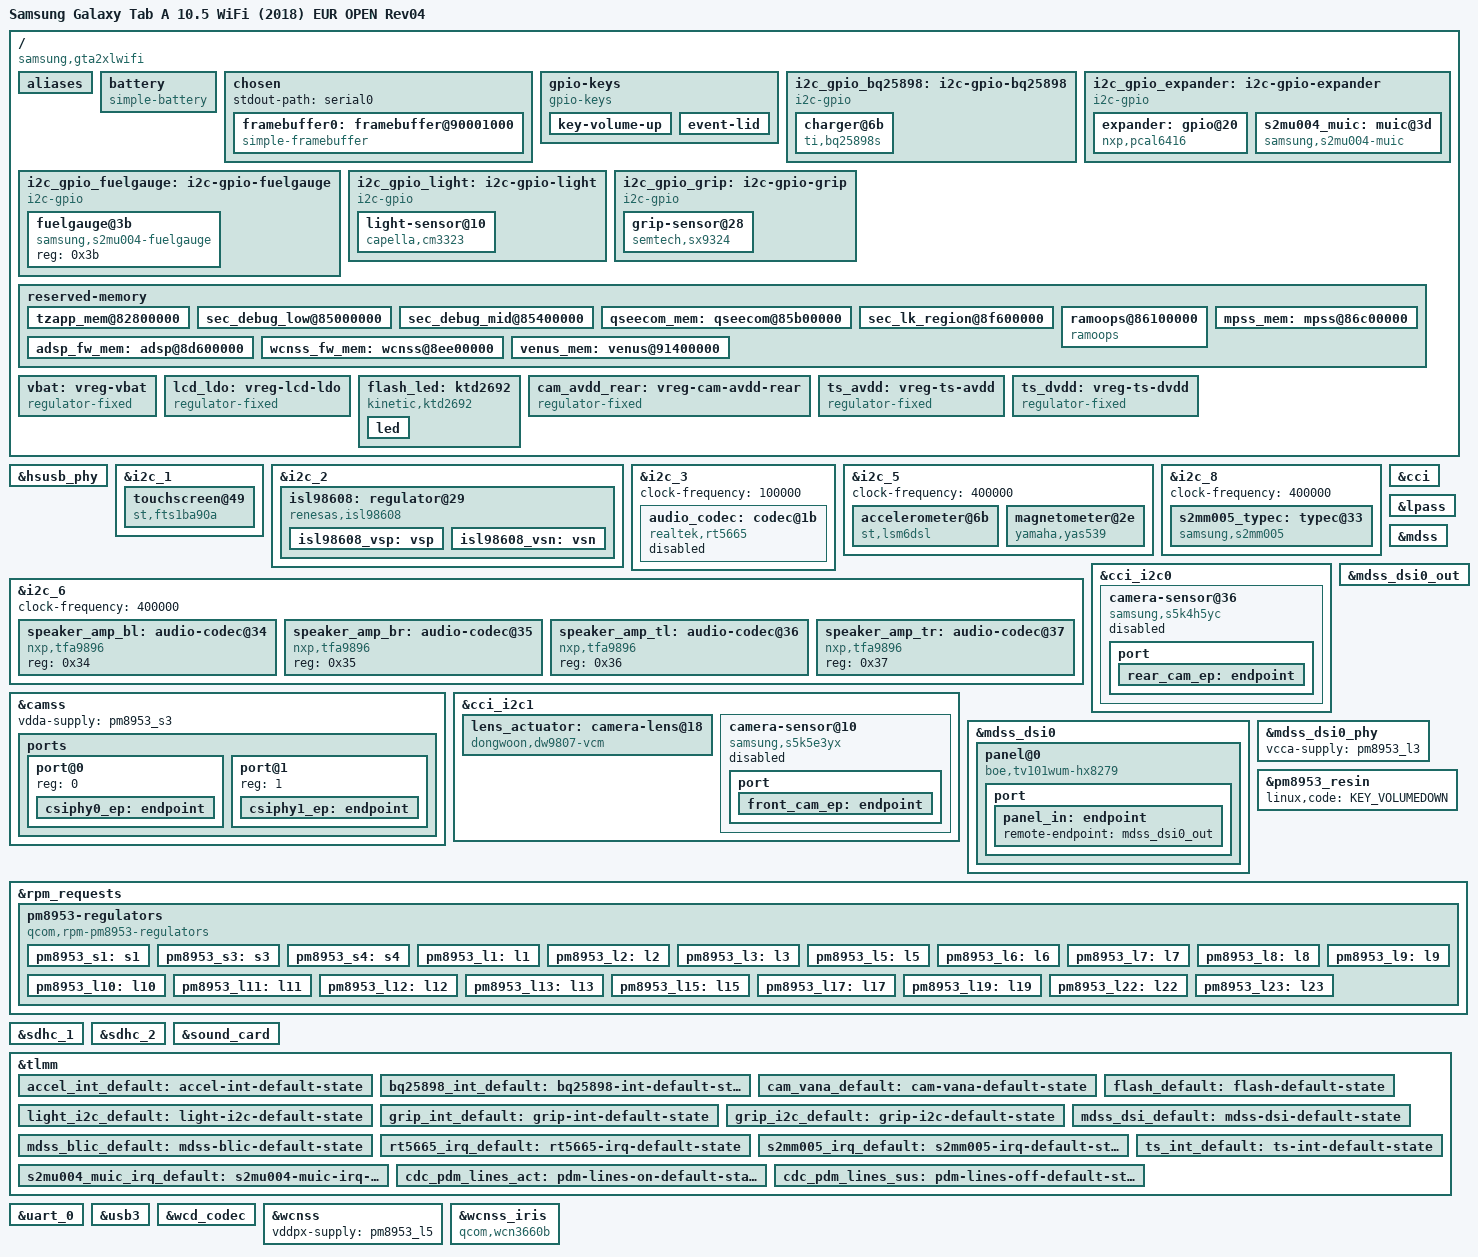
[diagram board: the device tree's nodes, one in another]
// SPDX-License-Identifier: BSD-3-Clause
// Copyright (c) 2025, The Linux Foundation. All rights reserved.

/dts-v1/;

#include "sdm450.dtsi"
#include "pm8953.dtsi"
#include <dt-bindings/leds/common.h>

/delete-node/ &wcnss_fw_mem;

/ {
	model = "Samsung Galaxy Tab A 10.5 WiFi (2018) EUR OPEN Rev04";
	compatible = "samsung,gta2xlwifi", "qcom,sdm450";
	chassis-type = "tablet";
	qcom,msm-id = <351 0>;
	qcom,board-id = <8 5>;

	aliases {
		mmc0 = &sdhc_1;
		mmc1 = &sdhc_2;
		i2c1 = &i2c_1;
		i2c2 = &i2c_2;
		i2c3 = &i2c_3;
		i2c5 = &i2c_5;
		i2c6 = &i2c_6;
		i2c8 = &i2c_8;
		i2c11 = &i2c_gpio_bq25898;
		i2c12 = &i2c_gpio_expander;
		i2c13 = &i2c_gpio_fuelgauge;
		i2c14 = &i2c_gpio_light;
		i2c15 = &i2c_gpio_grip;
		i2c20 = &cci_i2c0;
		i2c21 = &cci_i2c1;
		serial0 = &uart_0;
	};

	battery: battery {
		compatible = "simple-battery";
		device-chemistry = "lithium-ion";
		charge-full-design-microamp-hours = <7300000>;
		charge-term-current-microamp = <128000>;
		constant-charge-current-max-microamp = <2600000>;
		constant-charge-voltage-max-microvolt = <4304000>;
		voltage-max-design-microvolt = <4304000>;
		voltage-min-design-microvolt = <3200000>;
		alert-celsius = <0 50>;
		operating-range-celsius = <0 50>;
	};

	chosen {
		stdout-path = "serial0";
		#address-cells = <2>;
		#size-cells = <2>;
		ranges;

		framebuffer0: framebuffer@90001000 {
			compatible = "simple-framebuffer";
			reg = <0 0x90001000 0 (1920 * 1200 * 3)>;
			width = <1200>;
			height = <1920>;
			stride = <(1200 * 3)>;
			format = "r8g8b8";
			power-domains = <&gcc MDSS_GDSC>;
			clocks = <&gcc GCC_MDSS_AHB_CLK>,
				 <&gcc GCC_MDSS_AXI_CLK>,
				 <&gcc GCC_MDSS_VSYNC_CLK>,
				 <&gcc GCC_MDSS_MDP_CLK>,
				 <&gcc GCC_MDSS_BYTE0_CLK>,
				 <&gcc GCC_MDSS_PCLK0_CLK>,
				 <&gcc GCC_MDSS_ESC0_CLK>;
		};
	};

	gpio-keys {
		compatible = "gpio-keys";

		key-volume-up {
			label = "Volume Up";
			gpios = <&tlmm 85 GPIO_ACTIVE_LOW>;
			linux,code = <KEY_VOLUMEUP>;
			wakeup-source;
		};

		event-lid {
			label = "Hall Effect Sensor";
			gpios = <&tlmm 44 GPIO_ACTIVE_LOW>;
			linux,input-type = <EV_SW>;
			linux,code = <SW_LID>;
			linux,can-disable;
		};
	};

	/* BQ25898S sub-charger: I2C on GPIOs 16/17 */
	i2c_gpio_bq25898: i2c-gpio-bq25898 {
		compatible = "i2c-gpio";
		sda-gpios = <&tlmm 16 (GPIO_ACTIVE_HIGH|GPIO_OPEN_DRAIN)>;
		scl-gpios = <&tlmm 17 (GPIO_ACTIVE_HIGH|GPIO_OPEN_DRAIN)>;
		#address-cells = <1>;
		#size-cells = <0>;

		charger@6b {
			compatible = "ti,bq25898s", "ti,bq25890";
			reg = <0x6b>;
			interrupts-extended = <&tlmm 28 IRQ_TYPE_EDGE_FALLING>;
			pinctrl-0 = <&bq25898_int_default>;
			pinctrl-names = "default";
			monitored-battery = <&battery>;

			linux,skip-reset;

			/*
			 * Charging parameters from downstream Samsung
			 * multi-charger config and battery spec.
			 */
			ti,charge-current = <2600000>;
			ti,battery-regulation-voltage = <4304000>;
			ti,termination-current = <128000>;
			ti,precharge-current = <128000>;
			ti,minimum-sys-voltage = <3500000>;
			ti,boost-voltage = <5000000>;
			ti,boost-max-current = <1400000>;
		};
	};

	/* PCAL6416A GPIO expander + S2MU004 MUIC: I2C on GPIOs 21/20 */
	i2c_gpio_expander: i2c-gpio-expander {
		compatible = "i2c-gpio";
		sda-gpios = <&tlmm 21 (GPIO_ACTIVE_HIGH|GPIO_OPEN_DRAIN)>;
		scl-gpios = <&tlmm 20 (GPIO_ACTIVE_HIGH|GPIO_OPEN_DRAIN)>;
		i2c-gpio,delay-us = <2>;
		#address-cells = <1>;
		#size-cells = <0>;

		expander: gpio@20 {
			compatible = "nxp,pcal6416";
			reg = <0x20>;
			reset-gpios = <&tlmm 33 GPIO_ACTIVE_LOW>;
			vcc-supply = <&pm8953_l5>;
			gpio-controller;
			#gpio-cells = <2>;
		};

		/* S2MU004 MUIC – routes USB D+/D− through analog switches */
		s2mu004_muic: muic@3d {
			compatible = "samsung,s2mu004-muic";
			reg = <0x3d>;
			interrupts-extended = <&tlmm 73 IRQ_TYPE_EDGE_FALLING>;
			pinctrl-0 = <&s2mu004_muic_irq_default>;
			pinctrl-names = "default";
		};
	};

	/* S2MU004 fuel gauge: I2C on GPIOs 39/38 */
	i2c_gpio_fuelgauge: i2c-gpio-fuelgauge {
		compatible = "i2c-gpio";
		sda-gpios = <&tlmm 39 (GPIO_ACTIVE_HIGH|GPIO_OPEN_DRAIN)>;
		scl-gpios = <&tlmm 38 (GPIO_ACTIVE_HIGH|GPIO_OPEN_DRAIN)>;
		#address-cells = <1>;
		#size-cells = <0>;

		fuelgauge@3b {
			compatible = "samsung,s2mu004-fuelgauge";
			reg = <0x3b>;
		};
	};

	/* CM3323 light sensor: I2C on GPIOs 68/69 */
	i2c_gpio_light: i2c-gpio-light {
		compatible = "i2c-gpio";
		sda-gpios = <&tlmm 68 (GPIO_ACTIVE_HIGH|GPIO_OPEN_DRAIN)>;
		scl-gpios = <&tlmm 69 (GPIO_ACTIVE_HIGH|GPIO_OPEN_DRAIN)>;
		i2c-gpio,delay-us = <2>;
		pinctrl-0 = <&light_i2c_default>;
		pinctrl-names = "default";
		#address-cells = <1>;
		#size-cells = <0>;

		light-sensor@10 {
			compatible = "capella,cm3323";
			reg = <0x10>;
			vdd-supply = <&pm8953_l10>;
		};
	};

	/* SX9320 grip/SAR sensor: I2C on GPIOs 64/65 */
	i2c_gpio_grip: i2c-gpio-grip {
		compatible = "i2c-gpio";
		sda-gpios = <&tlmm 64 (GPIO_ACTIVE_HIGH|GPIO_OPEN_DRAIN)>;
		scl-gpios = <&tlmm 65 (GPIO_ACTIVE_HIGH|GPIO_OPEN_DRAIN)>;
		pinctrl-0 = <&grip_i2c_default>;
		pinctrl-names = "default";
		#address-cells = <1>;
		#size-cells = <0>;

		grip-sensor@28 {
			compatible = "semtech,sx9324";
			reg = <0x28>;
			interrupts-extended = <&tlmm 61 IRQ_TYPE_LEVEL_LOW>;
			pinctrl-0 = <&grip_int_default>;
			pinctrl-names = "default";
			#io-channel-cells = <0>;
		};
	};

	reserved-memory {
		tzapp_mem@82800000 {
			reg = <0x0 0x82800000 0x0 0x2800000>;
			no-map;
		};

		sec_debug_low@85000000 {
			reg = <0x0 0x85000000 0x0 0x400000>;
			no-map;
		};

		sec_debug_mid@85400000 {
			reg = <0x0 0x85400000 0x0 0x400000>;
			no-map;
		};

		qseecom_mem: qseecom@85b00000 {
			reg = <0x0 0x85b00000 0x0 0x600000>;
			no-map;
		};

		sec_lk_region@8f600000 {
			reg = <0x0 0x8f600000 0x0 0x300000>;
			no-map;
		};

		ramoops@86100000 {
			compatible = "ramoops";
			reg = <0 0x86100000 0 0x100000>;

			console-size = <0x40000>;
			ftrace-size = <0x40000>;
			pmsg-size = <0x40000>;
			record-size = <0x40000>;
		};

		mpss_mem: mpss@86c00000 {
			reg = <0x0 0x86c00000 0x0 0x6400000>;
			no-map;
		};

		adsp_fw_mem: adsp@8d600000 {
			reg = <0x0 0x8d600000 0x0 0x1800000>;
			no-map;
		};

		wcnss_fw_mem: wcnss@8ee00000 {
			reg = <0x0 0x8ee00000 0x0 0x700000>;
			no-map;
		};

		venus_mem: venus@91400000 {
			reg = <0x0 0x91400000 0x0 0x500000>;
			no-map;
		};
	};

	vbat: vreg-vbat {
		compatible = "regulator-fixed";
		regulator-always-on;
		regulator-max-microvolt = <3700000>;
		regulator-min-microvolt = <3700000>;
		regulator-name = "VBAT";
	};

	/*
	 * LCD LDO enable (VDDR) on GPIO 35.
	 * Used as iovcc supply for the panel. Declared at 1.8V for
	 * the panel-himax-hx8279 driver's voltage check; actual
	 * hardware output is ~1.5V.
	 */
	lcd_ldo: vreg-lcd-ldo {
		compatible = "regulator-fixed";
		enable-active-high;
		gpio = <&tlmm 35 GPIO_ACTIVE_HIGH>;
		regulator-boot-on;
		regulator-max-microvolt = <1800000>;
		regulator-min-microvolt = <1800000>;
		regulator-name = "lcd_ldo";
		startup-delay-us = <200>;
		vin-supply = <&pm8953_s4>;
	};

	/*
	 * ISL98608 display power IC is now handled via I2C (see &i2c_2).
	 * The old regulator-fixed on GPIO 134 is replaced by a proper
	 * regulator driver that programs VSP/VSN voltages over I2C
	 * before asserting the enable pin.
	 */

	/* KTD2692 camera flash LED on GPIO 36 */
	flash_led: ktd2692 {
		compatible = "kinetic,ktd2692";
		ctrl-gpios = <&tlmm 36 GPIO_ACTIVE_HIGH>;
		pinctrl-0 = <&flash_default>;
		pinctrl-names = "default";
		vin-supply = <&vbat>;

		led {
			function = LED_FUNCTION_FLASH;
			color = <LED_COLOR_ID_WHITE>;
			flash-max-timeout-us = <250000>;
			flash-max-microamp = <300000>;
			led-max-microamp = <100000>;
		};
	};

	/* Rear camera AVDD 2.8V on GPIO 89 */
	cam_avdd_rear: vreg-cam-avdd-rear {
		compatible = "regulator-fixed";
		enable-active-high;
		gpio = <&tlmm 89 GPIO_ACTIVE_HIGH>;
		pinctrl-0 = <&cam_vana_default>;
		pinctrl-names = "default";
		regulator-max-microvolt = <2800000>;
		regulator-min-microvolt = <2800000>;
		regulator-name = "cam_avdd_rear";
		vin-supply = <&vbat>;
	};

	/* Touchscreen AVDD 3.3V on GPIO 139 */
	ts_avdd: vreg-ts-avdd {
		compatible = "regulator-fixed";
		enable-active-high;
		gpio = <&tlmm 139 GPIO_ACTIVE_HIGH>;
		regulator-boot-on;
		regulator-max-microvolt = <3300000>;
		regulator-min-microvolt = <3300000>;
		regulator-name = "ts_avdd";
		startup-delay-us = <200>;
		vin-supply = <&vbat>;
	};

	/* Touchscreen DVDD 1.8V on GPIO 140 */
	ts_dvdd: vreg-ts-dvdd {
		compatible = "regulator-fixed";
		enable-active-high;
		gpio = <&tlmm 140 GPIO_ACTIVE_HIGH>;
		regulator-boot-on;
		regulator-max-microvolt = <1800000>;
		regulator-min-microvolt = <1800000>;
		regulator-name = "ts_dvdd";
		startup-delay-us = <200>;
		vin-supply = <&pm8953_s4>;
	};
};

&hsusb_phy {
	vdd-supply = <&pm8953_l3>;
	vdda-pll-supply = <&pm8953_l7>;
	vdda-phy-dpdm-supply = <&pm8953_l13>;

	/* Samsung-specific PHY tuning (from downstream qusb-phy-init-seq) */
	qcom,hstx-trim-value = <12>;		/* 0xC (downstream TUNE1=0xC0) */
	qcom,preemphasis-level = <0>;		/* no pre-emphasis */

	status = "okay";
};

/* Touchscreen: STMicroelectronics FTS1BA90A */
&i2c_1 {
	status = "okay";

	touchscreen@49 {
		compatible = "st,fts1ba90a";
		reg = <0x49>;
		interrupts-extended = <&tlmm 59 IRQ_TYPE_LEVEL_LOW>;
		pinctrl-0 = <&ts_int_default>;
		pinctrl-names = "default";
		avdd-supply = <&ts_avdd>;
		vdd-supply = <&ts_dvdd>;
		touchscreen-size-x = <1199>;
		touchscreen-size-y = <1919>;
	};
};

/* ISL98608 display power IC (I2C address 0x29) */
&i2c_2 {
	status = "okay";

	isl98608: regulator@29 {
		compatible = "renesas,isl98608";
		reg = <0x29>;
		enable-gpios = <&tlmm 134 GPIO_ACTIVE_HIGH>;
		pinctrl-0 = <&mdss_blic_default>;
		pinctrl-names = "default";

		isl98608_vsp: vsp {
			regulator-name = "lcd_vsp";
			regulator-min-microvolt = <5000000>;
			regulator-max-microvolt = <5800000>;
			regulator-boot-on;
		};

		isl98608_vsn: vsn {
			regulator-name = "lcd_vsn";
			regulator-min-microvolt = <5000000>;
			regulator-max-microvolt = <5800000>;
			regulator-boot-on;
		};
	};
};

/* Audio codec: Realtek RT5665 */
&i2c_3 {
	clock-frequency = <100000>;
	status = "okay";

	audio_codec: codec@1b {
		compatible = "realtek,rt5665";
		reg = <0x1b>;
		interrupts-extended = <&tlmm 72 IRQ_TYPE_LEVEL_LOW>;
		pinctrl-0 = <&rt5665_irq_default>;
		pinctrl-names = "default";
		realtek,in1-differential;
		realtek,in3-differential;
		realtek,in4-differential;
		realtek,jd-src = <2>;
		/* No mainline driver yet — node present for completeness */
		status = "disabled";
	};
};

/* Accelerometer/gyro: STMicroelectronics LSM6DSL + Magnetometer: Yamaha YAS539 */
&i2c_5 {
	clock-frequency = <400000>;
	status = "okay";

	accelerometer@6b {
		compatible = "st,lsm6dsl";
		reg = <0x6b>;
		interrupts-extended = <&tlmm 42 IRQ_TYPE_LEVEL_HIGH>;
		pinctrl-0 = <&accel_int_default>;
		pinctrl-names = "default";
		vdd-supply = <&pm8953_l10>;
		vddio-supply = <&pm8953_l5>;
		mount-matrix = "0", "1", "0",
			       "1", "0", "0",
			       "0", "0", "-1";
	};

	magnetometer@2e {
		compatible = "yamaha,yas539";
		reg = <0x2e>;
		vdd-supply = <&pm8953_l10>;
		/* Vendor orientation = <5> → 180° yaw + Z-flip */
		mount-matrix = "-1", "0", "0",
			       "0", "1", "0",
			       "0", "0", "-1";
	};
};

/* Audio amplifiers: 4x NXP TFA9896 */
&i2c_6 {
	clock-frequency = <400000>;
	status = "okay";

	speaker_amp_bl: audio-codec@34 {
		compatible = "nxp,tfa9896";
		reg = <0x34>;
		#sound-dai-cells = <0>;
	};

	speaker_amp_br: audio-codec@35 {
		compatible = "nxp,tfa9896";
		reg = <0x35>;
		#sound-dai-cells = <0>;
	};

	speaker_amp_tl: audio-codec@36 {
		compatible = "nxp,tfa9896";
		reg = <0x36>;
		#sound-dai-cells = <0>;
	};

	speaker_amp_tr: audio-codec@37 {
		compatible = "nxp,tfa9896";
		reg = <0x37>;
		#sound-dai-cells = <0>;
	};
};

/* S2MM005 USB Type-C CC/PD controller on BLSP2 QUP4 (I2C8) */
&i2c_8 {
	clock-frequency = <400000>; /* downstream runs s2mm005 at 400kHz */
	status = "okay";

	s2mm005_typec: typec@33 {
		compatible = "samsung,s2mm005";
		reg = <0x33>;
		interrupts-extended = <&tlmm 141 IRQ_TYPE_EDGE_FALLING>;

		pinctrl-names = "default";
		pinctrl-0 = <&s2mm005_irq_default>;
	};
};

&camss {
	vdda-supply = <&pm8953_s3>;
	status = "okay";

	ports {
		port@0 {
			reg = <0>;

			csiphy0_ep: endpoint {
				clock-lanes = <7>;
				data-lanes = <0 1>;
				remote-endpoint = <&rear_cam_ep>;
			};
		};

		port@1 {
			reg = <1>;

			csiphy1_ep: endpoint {
				clock-lanes = <7>;
				data-lanes = <0 1>;
				remote-endpoint = <&front_cam_ep>;
			};
		};
	};
};

&cci {
	pinctrl-0 = <&cci0_default>,
		    <&cci1_default>,
		    <&camss_mclk0_default>,
		    <&camss_mclk1_default>;
	pinctrl-names = "default";
	status = "okay";
};

/* Rear camera: Samsung S5K4H5YC 8MP on CCI0 */
&cci_i2c0 {
	camera-sensor@36 {
		compatible = "samsung,s5k4h5yc";
		reg = <0x36>;
		clocks = <&gcc GCC_CAMSS_MCLK0_CLK>;
		clock-frequency = <24000000>;
		reset-gpios = <&tlmm 40 GPIO_ACTIVE_LOW>;
		dvdd-supply = <&pm8953_l2>;
		avdd-supply = <&cam_avdd_rear>;
		vio-supply = <&pm8953_l15>;
		flash-leds = <&flash_led>;
		lens-focus = <&lens_actuator>;
		rotation = <90>;
		orientation = <1>;
		/* No mainline driver yet */
		status = "disabled";

		port {
			rear_cam_ep: endpoint {
				data-lanes = <0 1>;
				remote-endpoint = <&csiphy0_ep>;
			};
		};
	};
};

/* Front camera: Samsung S5K5E3YX 5MP + DW9807 actuator on CCI1 */
&cci_i2c1 {
	lens_actuator: camera-lens@18 {
		compatible = "dongwoon,dw9807-vcm";
		reg = <0x18>;
		vdd-supply = <&pm8953_l17>;
	};

	camera-sensor@10 {
		compatible = "samsung,s5k5e3yx";
		reg = <0x10>;
		clocks = <&gcc GCC_CAMSS_MCLK1_CLK>;
		clock-frequency = <24000000>;
		reset-gpios = <&tlmm 129 GPIO_ACTIVE_LOW>;
		dvdd-supply = <&pm8953_l23>;
		avdd-supply = <&pm8953_l22>;
		vio-supply = <&pm8953_l15>;
		rotation = <270>;
		orientation = <0>;
		/* No mainline driver yet */
		status = "disabled";

		port {
			front_cam_ep: endpoint {
				data-lanes = <0 1>;
				remote-endpoint = <&csiphy1_ep>;
			};
		};
	};
};

&lpass {
	status = "okay";
};

&mdss {
	status = "okay";
};

&mdss_dsi0 {
	pinctrl-0 = <&mdss_dsi_default>;
	pinctrl-names = "default";
	vdda-supply = <&pm8953_s3>;
	vddio-supply = <&pm8953_l6>;
	status = "okay";

	panel@0 {
		/*
		 * BOE TV101WUM 10.5" 1200x1920 WUXGA IPS LCD panel
		 * with Himax HX8279 controller IC.
		 */
		compatible = "boe,tv101wum-hx8279";
		reg = <0>;
		reset-gpios = <&tlmm 50 GPIO_ACTIVE_HIGH>;
		vdd-supply = <&isl98608_vsp>;
		iovcc-supply = <&lcd_ldo>;

		port {
			panel_in: endpoint {
				remote-endpoint = <&mdss_dsi0_out>;
			};
		};
	};
};

&mdss_dsi0_out {
	data-lanes = <0 1 2 3>;
	remote-endpoint = <&panel_in>;
};

&mdss_dsi0_phy {
	vcca-supply = <&pm8953_l3>;
	status = "okay";
};

&pm8953_resin {
	linux,code = <KEY_VOLUMEDOWN>;
	status = "okay";
};

&rpm_requests {
	pm8953-regulators {
		compatible = "qcom,rpm-pm8953-regulators";
		vdd_s1-supply = <&vbat>;
		vdd_s2-supply = <&vbat>;
		vdd_s3-supply = <&vbat>;
		vdd_s4-supply = <&vbat>;
		vdd_s5-supply = <&vbat>;
		vdd_s6-supply = <&vbat>;
		vdd_s7-supply = <&vbat>;
		vdd_l1-supply = <&pm8953_s3>;
		vdd_l2_l3-supply = <&pm8953_s3>;
		vdd_l4_l5_l6_l7_l16_l19-supply = <&pm8953_s4>;
		vdd_l8_l11_l12_l13_l14_l15-supply = <&vbat>;
		vdd_l9_l10_l17_l18_l22-supply = <&vbat>;
		vdd_l23-supply = <&pm8953_s3>;

		pm8953_s1: s1 {
			regulator-min-microvolt = <864000>;
			regulator-max-microvolt = <1152000>;
		};

		pm8953_s3: s3 {
			regulator-min-microvolt = <1224000>;
			regulator-max-microvolt = <1224000>;
		};

		pm8953_s4: s4 {
			regulator-min-microvolt = <1896000>;
			regulator-max-microvolt = <2048000>;
		};

		pm8953_l1: l1 {
			regulator-min-microvolt = <1000000>;
			regulator-max-microvolt = <1100000>;
		};

		pm8953_l2: l2 {
			regulator-min-microvolt = <1200000>;
			regulator-max-microvolt = <1200000>;
		};

		pm8953_l3: l3 {
			regulator-min-microvolt = <925000>;
			regulator-max-microvolt = <925000>;
			regulator-allow-set-load;
		};

		pm8953_l5: l5 {
			regulator-min-microvolt = <1800000>;
			regulator-max-microvolt = <1800000>;
			regulator-always-on;
		};

		pm8953_l6: l6 {
			regulator-min-microvolt = <1800000>;
			regulator-max-microvolt = <1800000>;
		};

		pm8953_l7: l7 {
			regulator-min-microvolt = <1800000>;
			regulator-max-microvolt = <1900000>;
		};

		pm8953_l8: l8 {
			regulator-min-microvolt = <2900000>;
			regulator-max-microvolt = <2900000>;
		};

		pm8953_l9: l9 {
			regulator-min-microvolt = <3000000>;
			regulator-max-microvolt = <3300000>;
		};

		pm8953_l10: l10 {
			regulator-min-microvolt = <2800000>;
			regulator-max-microvolt = <3000000>;
		};

		pm8953_l11: l11 {
			regulator-min-microvolt = <2800000>;
			regulator-max-microvolt = <3000000>;
		};

		pm8953_l12: l12 {
			regulator-min-microvolt = <1800000>;
			regulator-max-microvolt = <3000000>;
		};

		pm8953_l13: l13 {
			regulator-min-microvolt = <3075000>;
			regulator-max-microvolt = <3125000>;
		};

		pm8953_l15: l15 {
			regulator-min-microvolt = <1800000>;
			regulator-max-microvolt = <1800000>;
		};

		pm8953_l17: l17 {
			regulator-min-microvolt = <2800000>;
			regulator-max-microvolt = <3000000>;
		};

		pm8953_l19: l19 {
			regulator-min-microvolt = <1200000>;
			regulator-max-microvolt = <1350000>;
		};

		pm8953_l22: l22 {
			regulator-min-microvolt = <2800000>;
			regulator-max-microvolt = <2800000>;
		};

		pm8953_l23: l23 {
			regulator-min-microvolt = <975000>;
			regulator-max-microvolt = <1225000>;
		};
	};
};

&sdhc_1 {
	vmmc-supply = <&pm8953_l8>;
	vqmmc-supply = <&pm8953_l5>;
	status = "okay";
};

&sdhc_2 {
	cd-gpios = <&tlmm 133 GPIO_ACTIVE_LOW>;
	pinctrl-0 = <&sdc2_clk_on &sdc2_cmd_on &sdc2_data_on &sdc2_cd_off>;
	pinctrl-1 = <&sdc2_clk_off &sdc2_cmd_off &sdc2_data_off &sdc2_cd_off>;
	pinctrl-names = "default", "sleep";
	vmmc-supply = <&pm8953_l11>;
	vqmmc-supply = <&pm8953_l12>;
	status = "okay";
};

&sound_card {
	model = "samsung-gta2xl";
	audio-routing =
		"AMIC1", "MIC BIAS External1",
		"AMIC2", "MIC BIAS Internal2",
		"AMIC3", "MIC BIAS External1";
	/*
	 * GPIOs 67/68 (cdc_pdm_comp) and 69 (cdc_pdm) are used by the
	 * light sensor I2C bus, so we override those pinctrl groups to
	 * exclude the conflicting pins.
	 */
	pinctrl-0 = <&cdc_pdm_lines_act &cdc_pdm_lines_2_act>;
	pinctrl-1 = <&cdc_pdm_lines_sus &cdc_pdm_lines_2_sus>;
	pinctrl-names = "default", "sleep";
	status = "okay";
};

&tlmm {
	accel_int_default: accel-int-default-state {
		pins = "gpio42";
		function = "gpio";
		bias-disable;
	};

	bq25898_int_default: bq25898-int-default-state {
		pins = "gpio28";
		function = "gpio";
		bias-disable;
	};

	cam_vana_default: cam-vana-default-state {
		pins = "gpio89";
		function = "gpio";
		bias-disable;
		drive-strength = <2>;
	};

	flash_default: flash-default-state {
		pins = "gpio36";
		function = "gpio";
		bias-disable;
		drive-strength = <2>;
	};

	light_i2c_default: light-i2c-default-state {
		pins = "gpio68", "gpio69";
		function = "gpio";
		bias-disable;
		drive-strength = <2>;
	};

	grip_int_default: grip-int-default-state {
		pins = "gpio61";
		function = "gpio";
		bias-disable;
	};

	grip_i2c_default: grip-i2c-default-state {
		pins = "gpio64", "gpio65";
		function = "gpio";
		bias-disable;
		drive-strength = <2>;
	};

	mdss_dsi_default: mdss-dsi-default-state {
		pins = "gpio50";
		function = "gpio";
		drive-strength = <8>;
		bias-disable;
		output-high;
	};

	mdss_blic_default: mdss-blic-default-state {
		pins = "gpio134";
		function = "gpio";
		drive-strength = <8>;
		bias-disable;
	};

	rt5665_irq_default: rt5665-irq-default-state {
		pins = "gpio72";
		function = "gpio";
		bias-pull-up;
	};

	s2mm005_irq_default: s2mm005-irq-default-state {
		pins = "gpio141";
		function = "gpio";
		bias-disable;
	};

	s2mu004_muic_irq_default: s2mu004-muic-irq-default-state {
		pins = "gpio73";
		function = "gpio";
		bias-pull-up;
	};

	ts_int_default: ts-int-default-state {
		pins = "gpio59";
		function = "gpio";
		bias-disable;
	};

	/*
	 * Override msm8953.dtsi PDM pinctrl to exclude gpio67/68/69:
	 * those are used by the light sensor I2C bus on this board.
	 */
	/delete-node/ pdm-lines-on-default-state;
	cdc_pdm_lines_act: pdm-lines-on-default-state {
		pins = "gpio73", "gpio74";
		function = "cdc_pdm0";
		drive-strength = <8>;
	};

	/delete-node/ pdm-lines-off-default-state;
	cdc_pdm_lines_sus: pdm-lines-off-default-state {
		pins = "gpio73", "gpio74";
		function = "cdc_pdm0";
		drive-strength = <2>;
		bias-disable;
	};
};

&uart_0 {
	status = "okay";
};

&usb3 {
	/delete-property/ usb-role-switch;
	/delete-property/ interconnects;
	/delete-property/ interconnect-names;
	dr_mode = "peripheral";

	/*
	 * Prevent the DWC3 from suspending the QUSB2 PHY when the USB link
	 * enters L2 (idle/suspend).  On this device the PHY de-asserts the
	 * D+ pull-up when UTMI SuspendM is active, so the host never sees
	 * the device if SUSPHY is left enabled.  The downstream dwc3-msm
	 * glue layer explicitly clears SUSPHY during device mode.
	 */
	snps,dis_u2_susphy_quirk;
	snps,dis_enblslpm_quirk;
	snps,usb2-gadget-lpm-disable;

	status = "okay";
};

&wcd_codec {
	qcom,micbias-lvl = <2800>;
	qcom,micbias1-ext-cap;
	qcom,micbias2-ext-cap;
	vdd-cdc-io-supply = <&pm8953_l5>;
	vdd-cdc-tx-rx-cx-supply = <&pm8953_s4>;
	vdd-micbias-supply = <&pm8953_l13>;
	status = "okay";
};

&wcnss {
	vddpx-supply = <&pm8953_l5>;
	status = "okay";
};

&wcnss_iris {
	compatible = "qcom,wcn3660b";
	vddxo-supply = <&pm8953_l7>;
	vddrfa-supply = <&pm8953_l19>;
	vddpa-supply = <&pm8953_l9>;
	vdddig-supply = <&pm8953_l5>;
	status = "okay";
};
